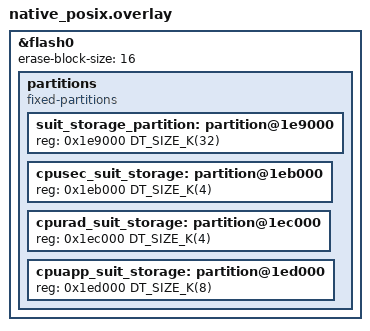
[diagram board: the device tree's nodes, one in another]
/*
 * Copyright (c) 2024 Nordic Semiconductor ASA
 *
 * SPDX-License-Identifier: LicenseRef-Nordic-5-Clause
 */

&flash0 {
	/* Align erase block size with the nRF54H20 MRAM definition. */
	erase-block-size = <16>;

	partitions {
		compatible = "fixed-partitions";
		#address-cells = <1>;
		#size-cells = <1>;

		/* Use the last 32 kB of SecDom SUIT NVM storage. */
		suit_storage_partition: partition@1e9000 {
			reg = <0x1e9000 DT_SIZE_K(32)>;
		};

		/* Use the first 4kB as area reserved for Secure domain. */
		cpusec_suit_storage: partition@1eb000 {
			reg = <0x1eb000 DT_SIZE_K(4)>;
		};

		/* Use the next 4kB as area reserved for Radio domain. */
		cpurad_suit_storage: partition@1ec000 {
			reg = <0x1ec000 DT_SIZE_K(4)>;
		};

		/* Use the next 8kB as area reserved for Application domain. */
		cpuapp_suit_storage: partition@1ed000 {
			reg = <0x1ed000 DT_SIZE_K(8)>;
		};
	};
};
